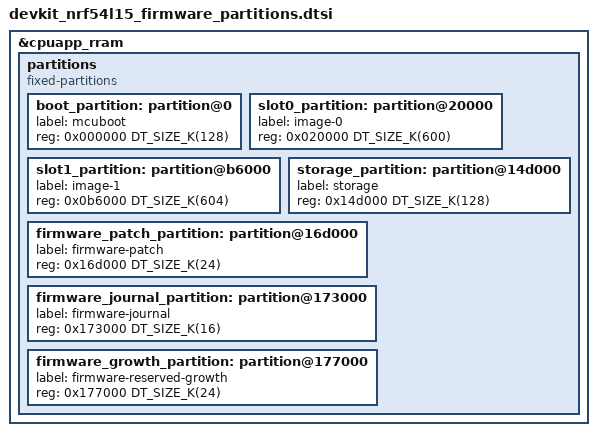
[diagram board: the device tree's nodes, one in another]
/* Copyright (c) 2026 FoBE Studio; SPDX-License-Identifier: Apache-2.0 */

/* Meshbus FIRMWARE partition ABI 1 for the 1524 KiB CPUAPP RRAM. */
&cpuapp_rram {
	/delete-node/ partitions;

	partitions {
		compatible = "fixed-partitions";
		#address-cells = <1>;
		#size-cells = <1>;
		ranges;

		boot_partition: partition@0 {
			label = "mcuboot";
			reg = <0x000000 DT_SIZE_K(128)>;
		};
		slot0_partition: partition@20000 {
			label = "image-0";
			reg = <0x020000 DT_SIZE_K(600)>;
		};
		slot1_partition: partition@b6000 {
			label = "image-1";
			reg = <0x0b6000 DT_SIZE_K(604)>;
		};
		storage_partition: partition@14d000 {
			label = "storage";
			reg = <0x14d000 DT_SIZE_K(128)>;
		};
		firmware_patch_partition: partition@16d000 {
			label = "firmware-patch";
			reg = <0x16d000 DT_SIZE_K(24)>;
		};
		firmware_journal_partition: partition@173000 {
			label = "firmware-journal";
			reg = <0x173000 DT_SIZE_K(16)>;
		};
		firmware_growth_partition: partition@177000 {
			label = "firmware-reserved-growth";
			reg = <0x177000 DT_SIZE_K(24)>;
		};
	};
};
